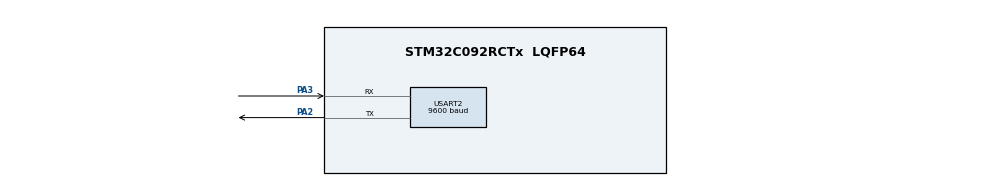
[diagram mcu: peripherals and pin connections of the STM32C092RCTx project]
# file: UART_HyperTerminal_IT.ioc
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Mcu.Family=STM32C0
Mcu.Name=STM32C092RCTx
Mcu.Package=LQFP64
NVIC.USART2_IRQn=true\:0\:0\:false\:false\:true\:true\:true\:true
PA2.GPIO_PuPd=GPIO_PULLUP
PA2.Mode=Asynchronous
PA2.Signal=USART2_TX
PA3.GPIO_PuPd=GPIO_PULLUP
PA3.Mode=Asynchronous
PA3.Signal=USART2_RX
ProjectManager.HeapSize=0x200
ProjectManager.StackSize=0x400
ProjectManager.TargetToolchain=EWARM V9.20
RCC.ADCFreq_Value=48000000
RCC.AHBFreq_Value=48000000
RCC.CortexFreq_Value=48000000
RCC.EXTERNAL_CLOCK_VALUE=12288000
RCC.HCLKFreq_Value=48000000
RCC.HSE_VALUE=8000000
RCC.HSISYSCLKDivider=RCC_HSI_DIV1
RCC.HSI_VALUE=48000000
RCC.LSE_VALUE=32768
RCC.SYSCLKFreq_VALUE=48000000
USART2.BaudRate=9600
USART2.ClockPrescaler=PRESCALER_DIV1
USART2.DMADisableonRxErrorParam=ADVFEATURE_DMA_ENABLEONRXERROR
USART2.DataInvertParam=ADVFEATURE_DATAINV_DISABLE
USART2.MSBFirstParam=ADVFEATURE_MSBFIRST_DISABLE
USART2.Mode=MODE_TX_RX
USART2.OneBitSampling=UART_ONE_BIT_SAMPLE_DISABLE
USART2.OverSampling=UART_OVERSAMPLING_16
USART2.OverrunDisableParam=ADVFEATURE_OVERRUN_ENABLE
USART2.Parity=PARITY_ODD
USART2.RxPinLevelInvertParam=ADVFEATURE_RXINV_DISABLE
USART2.StopBits=STOPBITS_1
USART2.SwapParam=ADVFEATURE_SWAP_DISABLE
USART2.TxPinLevelInvertParam=ADVFEATURE_TXINV_DISABLE
USART2.VirtualMode-Asynchronous=VM_ASYNC
USART2.WordLength=WORDLENGTH_8B
board=custom

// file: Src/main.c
/* USER CODE BEGIN Header */
/**
  ******************************************************************************
  * @file    UART/UART_HyperTerminal_IT/Src/main.c
  * @author  MCD Application Team
  * @brief   This sample code shows how to use UART HAL and LL APIs to transmit
  *          and receive a data buffer with a communication process based on IT;
  *          The communication is done with the Hyperterminal PC application;
  *          HAL driver is used to perform UART configuration,
  *          then TX/RX transfers procedures are based on LL APIs use
  ******************************************************************************
  * @attention
  *
  * Copyright (c) 2024 STMicroelectronics.
  * All rights reserved.
  *
  * This software is licensed under terms that can be found in the LICENSE file
  * in the root directory of this software component.
  * If no LICENSE file comes with this software, it is provided AS-IS.
  *
  ******************************************************************************
  */
/* USER CODE END Header */
#include "main.h"

UART_HandleTypeDef huart2;

/* USER CODE BEGIN PV */

/* UART handler declaration */
UART_HandleTypeDef UartHandle;
__IO uint8_t  ubTxComplete = 0;
__IO uint8_t  ubRxComplete = 0;

/* Buffer used for transmission */
uint8_t aTxStartMessage[] = "\n\r ****UART-Hyperterminal communication based on IT (Mixed HAL/LL usage) ****\n\r Enter 10 characters using keyboard :\n\r";
__IO uint32_t uwTxIndex = 0;
uint8_t ubSizeToSend = sizeof(aTxStartMessage);
uint8_t aTxEndMessage[] = "\n\r Example Finished\n\r";

/* Buffer used for reception */
uint8_t aRxBuffer[RXBUFFERSIZE];
__IO uint32_t uwRxIndex = 0;

/* USER CODE END PV */

void SystemClock_Config(void);
static void MX_GPIO_Init(void);
static void MX_USART2_UART_Init(void);

int main(void)
{

  /* USER CODE BEGIN 1 */
/* STM32C0xx HAL library initialization:
       - Configure the Flash prefetch
       - Systick timer is configured by default as source of time base, but user
         can eventually implement his proper time base source (a general purpose
         timer for example or other time source), keeping in mind that Time base
         duration should be kept 1ms since PPP_TIMEOUT_VALUEs are defined and
         handled in milliseconds basis.
       - Low Level Initialization
     */
  /* USER CODE END 1 */

  /* MCU Configuration--------------------------------------------------------*/

  /* Reset of all peripherals, Initializes the Flash interface and the Systick. */
  HAL_Init();

  /* USER CODE BEGIN Init */
  /* Configure leds */
  BSP_LED_Init(LED1);
  BSP_LED_Init(LED2);

  /* USER CODE END Init */

  /* Configure the system clock */
  SystemClock_Config();

  /* Initialize all configured peripherals */
  MX_GPIO_Init();
  MX_USART2_UART_Init();
  /* USER CODE BEGIN 2 */

  /*## Configure UART peripheral for reception process (using LL) ##########*/
  /* Any data received will be stored "aRxBuffer" buffer : the number max of
     data received is RXBUFFERSIZE */
  /* Enable RXNE and Error interrupts */
  LL_USART_EnableIT_RXNE(USART2);
  LL_USART_EnableIT_ERROR(USART2);

  /*## Start the transmission process (using LL) *##########################*/
  /* While the UART in reception process, user can transmit data from
     "aTxStartMessage" buffer */
  /* Start USART transmission : Will initiate TXE interrupt after TDR register is empty */
  LL_USART_TransmitData8(USART2, aTxStartMessage[uwTxIndex++]);

  /* Enable TXE interrupt */
  LL_USART_EnableIT_TXE(USART2);

  /*## Wait for the end of the transfer ###################################*/
  /* USART IRQ handler is not anymore routed to HAL_UART_IRQHandler() function
     and is now based on LL API functions use.
     Therefore, use of HAL IT based services is no more possible. */
  /*  Once TX transfer is completed, LED1 will toggle.
      Then, when RX transfer is completed, LED1 will turn On. */
  while (ubTxComplete == 0)
  {
  }

  while (ubRxComplete == 0)
  {
    BSP_LED_Toggle(LED1);
    HAL_Delay(250);
  }

  BSP_LED_On(LED1); /* stop blink and keeps ON */

  /*## Send the received Buffer ###########################################*/
  /* Even if use of HAL IT based services is no more possible, use of HAL Polling based services
     (as Transmit in polling mode) is still possible. */
  if(HAL_UART_Transmit(&huart2, (uint8_t*)aRxBuffer, RXBUFFERSIZE, 1000)!= HAL_OK)
  {
    /* Transfer error in transmission process */
    Error_Handler();
  }

  /*## Send the End Message ###############################################*/
  if(HAL_UART_Transmit(&huart2, (uint8_t*)aTxEndMessage, TXENDMESSAGESIZE, 1000)!= HAL_OK)
  {
    /* Transfer error in transmission process */
    Error_Handler();
  }

  /* USER CODE END 2 */

  /* Infinite loop */
  while (1)
  {

  }
}

void SystemClock_Config(void)
{
  RCC_OscInitTypeDef RCC_OscInitStruct = {0};
  RCC_ClkInitTypeDef RCC_ClkInitStruct = {0};

  __HAL_FLASH_SET_LATENCY(FLASH_LATENCY_1);

  /** Initializes the RCC Oscillators according to the specified parameters
  * in the RCC_OscInitTypeDef structure.
  */
  RCC_OscInitStruct.OscillatorType = RCC_OSCILLATORTYPE_HSI;
  RCC_OscInitStruct.HSIState = RCC_HSI_ON;
  RCC_OscInitStruct.HSIDiv = RCC_HSI_DIV1;
  RCC_OscInitStruct.HSICalibrationValue = RCC_HSICALIBRATION_DEFAULT;
  if (HAL_RCC_OscConfig(&RCC_OscInitStruct) != HAL_OK)
  {
    Error_Handler();
  }

  /** Initializes the CPU, AHB and APB buses clocks
  */
  RCC_ClkInitStruct.ClockType = RCC_CLOCKTYPE_HCLK|RCC_CLOCKTYPE_SYSCLK
                              |RCC_CLOCKTYPE_PCLK1;
  RCC_ClkInitStruct.SYSCLKSource = RCC_SYSCLKSOURCE_HSI;
  RCC_ClkInitStruct.SYSCLKDivider = RCC_SYSCLK_DIV1;
  RCC_ClkInitStruct.AHBCLKDivider = RCC_HCLK_DIV1;
  RCC_ClkInitStruct.APB1CLKDivider = RCC_APB1_DIV1;

  if (HAL_RCC_ClockConfig(&RCC_ClkInitStruct, FLASH_LATENCY_1) != HAL_OK)
  {
    Error_Handler();
  }
}

static void MX_USART2_UART_Init(void)
{

  huart2.Instance = USART2;
  huart2.Init.BaudRate = 9600;
  huart2.Init.WordLength = UART_WORDLENGTH_8B;
  huart2.Init.StopBits = UART_STOPBITS_1;
  huart2.Init.Parity = UART_PARITY_ODD;
  huart2.Init.Mode = UART_MODE_TX_RX;
  huart2.Init.HwFlowCtl = UART_HWCONTROL_NONE;
  huart2.Init.OverSampling = UART_OVERSAMPLING_16;
  huart2.Init.OneBitSampling = UART_ONE_BIT_SAMPLE_DISABLE;
  huart2.Init.ClockPrescaler = UART_PRESCALER_DIV1;
  huart2.AdvancedInit.AdvFeatureInit = UART_ADVFEATURE_NO_INIT;
  if (HAL_UART_Init(&huart2) != HAL_OK)
  {
    Error_Handler();
  }

}

static void MX_GPIO_Init(void)
{

  /* GPIO Ports Clock Enable */
  __HAL_RCC_GPIOA_CLK_ENABLE();

}

/* USER CODE BEGIN 4 */

/**
  * @brief  Rx Transfer completed callback
  * @note   This example shows a simple way to report end of IT Rx transfer, and
  *         you can add your own implementation.
  * @retval None
  */
void UART_CharReception_Callback(void)
{
  /* Read Received character. RXNE flag is cleared by reading of RDR register */
  aRxBuffer[uwRxIndex++] = LL_USART_ReceiveData8(USART2);

  /* Check if reception is completed (expected nb of bytes has been received) */
  if (uwRxIndex == RXBUFFERSIZE)
  {
    /* Set Reception complete boolean to 1 */
    ubRxComplete = 1;
  }
}

/**
  * @brief  Function called for achieving next TX Byte sending
  * @retval None
  */
void UART_TXEmpty_Callback(void)
{
  if(uwTxIndex == (ubSizeToSend - 1))
  {
    /* Disable TXE interrupt */
    LL_USART_DisableIT_TXE(USART2);

    /* Enable TC interrupt */
    LL_USART_EnableIT_TC(USART2);
  }

  /* Fill TDR with a new char */
  LL_USART_TransmitData8(USART2, aTxStartMessage[uwTxIndex++]);
}

/**
  * @brief  Function called at completion of last byte transmission
  * @retval None
  */
void UART_CharTransmitComplete_Callback(void)
{
  if(uwTxIndex == sizeof(aTxStartMessage))
  {
    uwTxIndex = 0;

    /* Disable TC interrupt */
    LL_USART_DisableIT_TC(USART2);

    /* Set Tx complete boolean to 1 */
    ubTxComplete = 1;
  }
}

/**
  * @brief  UART error callbacks
  * @note   This example shows a simple way to report transfer error, and you can
  *         add your own implementation.
  * @retval None
  */
void UART_Error_Callback(void)
{
  __IO uint32_t isr_reg;

  /* Disable USARTx_IRQn */
  NVIC_DisableIRQ(USART2_IRQn);

  /* Error handling example :
    - Read USART ISR register to identify flag that leads to IT raising
    - Perform corresponding error handling treatment according to flag
  */
  isr_reg = LL_USART_ReadReg(USART2, ISR);
  if (isr_reg & LL_USART_ISR_NE)
  {
    /* Turn LED2 on: Transfer error in reception/transmission process */
    BSP_LED_On(LED2);
  }
  else
  {
    /* Turn LED2 on: Transfer error in reception/transmission process */
    BSP_LED_On(LED2);
  }
}

/* USER CODE END 4 */

void Error_Handler(void)
{
  /* USER CODE BEGIN Error_Handler_Debug */
  /* User can add his own implementation to report the HAL error return state */
  /* Toggle LED2 for error */
  while(1)
  {
    BSP_LED_Toggle(LED2);
    HAL_Delay(1000);
  }
  /* USER CODE END Error_Handler_Debug */
}

#ifdef  USE_FULL_ASSERT
/**
  * @brief  Reports the name of the source file and the source line number
  *         where the assert_param error has occurred.
  * @param  file: pointer to the source file name
  * @param  line: assert_param error line source number
  * @retval None
  */
void assert_failed(uint8_t *file, uint32_t line)
{
  /* USER CODE BEGIN 6 */
  /* User can add his own implementation to report the file name and line number,
     tex: printf("Wrong parameters value: file %s on line %d\r\n", file, line) */

  /* Infinite Loop */
  while (1)
  {
  }
  /* USER CODE END 6 */
}
#endif /* USE_FULL_ASSERT */
